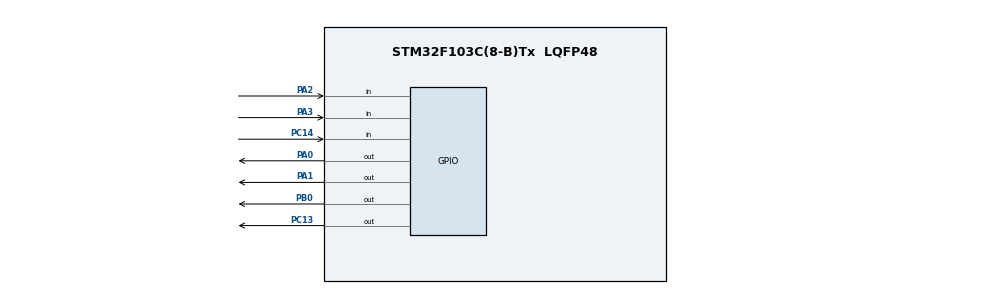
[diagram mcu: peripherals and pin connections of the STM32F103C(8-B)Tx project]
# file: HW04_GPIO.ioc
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Mcu.Family=STM32F1
Mcu.Name=STM32F103C(8-B)Tx
Mcu.Package=LQFP48
NVIC.PriorityGroup=NVIC_PRIORITYGROUP_4
PA0-WKUP.Signal=GPIO_Output
PA1.Signal=GPIO_Output
PA2.GPIO_PuPd=GPIO_PULLUP
PA2.Signal=GPIO_Input
PA3.GPIO_PuPd=GPIO_PULLUP
PA3.Signal=GPIO_Input
PB0.Signal=GPIO_Output
PC13-TAMPER-RTC.Signal=GPIO_Output
PC14-OSC32_IN.GPIO_PuPd=GPIO_PULLUP
PC14-OSC32_IN.Signal=GPIO_Input
ProjectManager.HeapSize=0x200
ProjectManager.StackSize=0x400
ProjectManager.TargetToolchain=CMake
RCC.APB1Freq_Value=8000000
RCC.APB2Freq_Value=8000000
VP_SYS_VS_ND.Mode=No_Debug
board=custom

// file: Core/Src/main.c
/* USER CODE BEGIN Header */
/**
  ******************************************************************************
  * @file           : main.c
  * @brief          : Main program body
  ******************************************************************************
  * @attention
  *
  * Copyright (c) 2026 STMicroelectronics.
  * All rights reserved.
  *
  * This software is licensed under terms that can be found in the LICENSE file
  * in the root directory of this software component.
  * If no LICENSE file comes with this software, it is provided AS-IS.
  *
  ******************************************************************************
  */
/* USER CODE END Header */
#include "main.h"

void SystemClock_Config(void);
static void MX_GPIO_Init(void);

/* USER CODE BEGIN 0 */
typedef enum { BTN_IDLE, BTN_DEBOUNCE, BTN_PRESSED } btn_state_t;
btn_state_t btn_state = BTN_IDLE;
uint32_t btn_timer = 0;
uint8_t led_blink_mode = 1;

uint32_t led_timer = 0;
/* USER CODE END 0 */

int main(void)
{

  /* MCU Configuration--------------------------------------------------------*/

  /* Reset of all peripherals, Initializes the Flash interface and the Systick. */
  HAL_Init();

  /* Configure the system clock */
  SystemClock_Config();

  /* Initialize all configured peripherals */
  MX_GPIO_Init();

  /* Infinite loop */
  while (1)
  {
    uint32_t current_tick = HAL_GetTick();

    // ==========================================
    // TASK 3: Blink LED PC13 (Non-blocking)
    // ==========================================
    if (led_blink_mode == 1) {
        if (current_tick - led_timer >= 500) {
            led_timer = current_tick;
            HAL_GPIO_TogglePin(GPIOC, GPIO_PIN_13);
        }
    } else {
        HAL_GPIO_WritePin(GPIOC, GPIO_PIN_13, GPIO_PIN_SET);
    }
    // ==========================================
    // TASK 4: Đọc nút nhấn PC14 chống dội FSM
    // ==========================================
    uint8_t btn_raw = HAL_GPIO_ReadPin(GPIOC, GPIO_PIN_14);

    switch (btn_state) {
        case BTN_IDLE:
            if (btn_raw == GPIO_PIN_RESET) {
                btn_state = BTN_DEBOUNCE;
                btn_timer = current_tick;
            }
            break;

        case BTN_DEBOUNCE:
            if (btn_raw == GPIO_PIN_SET) {
                btn_state = BTN_IDLE;
            } else if (current_tick - btn_timer >= 50) {
                btn_state = BTN_PRESSED;
            }
            break;

        case BTN_PRESSED:
            if (btn_raw == GPIO_PIN_SET) {
                led_blink_mode = !led_blink_mode;
                btn_state = BTN_IDLE;
            }
            break;
    }
    // ==========================================
    // TASK 5: Quét ma trận phím 2x2
    // ==========================================
    static const uint16_t ROW_PINS[2] = {GPIO_PIN_0, GPIO_PIN_1};
    static const uint16_t COL_PINS[2] = {GPIO_PIN_2, GPIO_PIN_3};
    uint8_t key_pressed = 0;

    for (uint8_t r = 0; r < 2; r++) {
        HAL_GPIO_WritePin(GPIOA, GPIO_PIN_0 | GPIO_PIN_1, GPIO_PIN_SET);
        HAL_GPIO_WritePin(GPIOA, ROW_PINS[r], GPIO_PIN_RESET);

        for(volatile int i = 0; i < 100; i++);

        for (uint8_t c = 0; c < 2; c++) {
            if (HAL_GPIO_ReadPin(GPIOA, COL_PINS[c]) == GPIO_PIN_RESET) {
                key_pressed = (r * 2 + c) + 1;
            }
        }
    }

    if (key_pressed != 0) {
        HAL_GPIO_WritePin(GPIOB, GPIO_PIN_0, GPIO_PIN_SET);
    } else {
        HAL_GPIO_WritePin(GPIOB, GPIO_PIN_0, GPIO_PIN_RESET);
    }

    /* USER CODE END WHILE */
  }
}

void SystemClock_Config(void)
{
  RCC_OscInitTypeDef RCC_OscInitStruct = {0};
  RCC_ClkInitTypeDef RCC_ClkInitStruct = {0};

  /** Initializes the RCC Oscillators according to the specified parameters
  * in the RCC_OscInitTypeDef structure.
  */
  RCC_OscInitStruct.OscillatorType = RCC_OSCILLATORTYPE_HSI;
  RCC_OscInitStruct.HSIState = RCC_HSI_ON;
  RCC_OscInitStruct.HSICalibrationValue = RCC_HSICALIBRATION_DEFAULT;
  RCC_OscInitStruct.PLL.PLLState = RCC_PLL_NONE;
  if (HAL_RCC_OscConfig(&RCC_OscInitStruct) != HAL_OK)
  {
    Error_Handler();
  }

  /** Initializes the CPU, AHB and APB buses clocks
  */
  RCC_ClkInitStruct.ClockType = RCC_CLOCKTYPE_HCLK|RCC_CLOCKTYPE_SYSCLK
                              |RCC_CLOCKTYPE_PCLK1|RCC_CLOCKTYPE_PCLK2;
  RCC_ClkInitStruct.SYSCLKSource = RCC_SYSCLKSOURCE_HSI;
  RCC_ClkInitStruct.AHBCLKDivider = RCC_SYSCLK_DIV1;
  RCC_ClkInitStruct.APB1CLKDivider = RCC_HCLK_DIV1;
  RCC_ClkInitStruct.APB2CLKDivider = RCC_HCLK_DIV1;

  if (HAL_RCC_ClockConfig(&RCC_ClkInitStruct, FLASH_LATENCY_0) != HAL_OK)
  {
    Error_Handler();
  }
}

static void MX_GPIO_Init(void)
{
  GPIO_InitTypeDef GPIO_InitStruct = {0};

  /* GPIO Ports Clock Enable */
  __HAL_RCC_GPIOC_CLK_ENABLE();
  __HAL_RCC_GPIOA_CLK_ENABLE();
  __HAL_RCC_GPIOB_CLK_ENABLE();

  /*Configure GPIO pin Output Level */
  HAL_GPIO_WritePin(GPIOC, GPIO_PIN_13, GPIO_PIN_RESET);

  /*Configure GPIO pin Output Level */
  HAL_GPIO_WritePin(GPIOA, GPIO_PIN_0|GPIO_PIN_1, GPIO_PIN_RESET);

  /*Configure GPIO pin Output Level */
  HAL_GPIO_WritePin(GPIOB, GPIO_PIN_0, GPIO_PIN_RESET);

  /*Configure GPIO pin : PC13 */
  GPIO_InitStruct.Pin = GPIO_PIN_13;
  GPIO_InitStruct.Mode = GPIO_MODE_OUTPUT_PP;
  GPIO_InitStruct.Pull = GPIO_NOPULL;
  GPIO_InitStruct.Speed = GPIO_SPEED_FREQ_LOW;
  HAL_GPIO_Init(GPIOC, &GPIO_InitStruct);

  /*Configure GPIO pin : PC14 */
  GPIO_InitStruct.Pin = GPIO_PIN_14;
  GPIO_InitStruct.Mode = GPIO_MODE_INPUT;
  GPIO_InitStruct.Pull = GPIO_PULLUP;
  HAL_GPIO_Init(GPIOC, &GPIO_InitStruct);

  /*Configure GPIO pins : PA0 PA1 */
  GPIO_InitStruct.Pin = GPIO_PIN_0|GPIO_PIN_1;
  GPIO_InitStruct.Mode = GPIO_MODE_OUTPUT_PP;
  GPIO_InitStruct.Pull = GPIO_NOPULL;
  GPIO_InitStruct.Speed = GPIO_SPEED_FREQ_LOW;
  HAL_GPIO_Init(GPIOA, &GPIO_InitStruct);

  /*Configure GPIO pins : PA2 PA3 */
  GPIO_InitStruct.Pin = GPIO_PIN_2|GPIO_PIN_3;
  GPIO_InitStruct.Mode = GPIO_MODE_INPUT;
  GPIO_InitStruct.Pull = GPIO_PULLUP;
  HAL_GPIO_Init(GPIOA, &GPIO_InitStruct);

  /*Configure GPIO pin : PB0 */
  GPIO_InitStruct.Pin = GPIO_PIN_0;
  GPIO_InitStruct.Mode = GPIO_MODE_OUTPUT_PP;
  GPIO_InitStruct.Pull = GPIO_NOPULL;
  GPIO_InitStruct.Speed = GPIO_SPEED_FREQ_LOW;
  HAL_GPIO_Init(GPIOB, &GPIO_InitStruct);

}

void Error_Handler(void)
{
  __disable_irq();
  while (1)
  {
  }
}
